# SAM9X75D1GN2 register map
Vendor: Microchip Technology; Series: SAM9X7; File version: 0
Registers are 32-bit, read-write, reset 0x0 unless marked. A register's access mark holds for its fields unless they carry their own. Offsets are from the block's base; [hi:lo] are bit positions.

## SCKC — Slow Clock Controller
Base 0xFFFFFE50
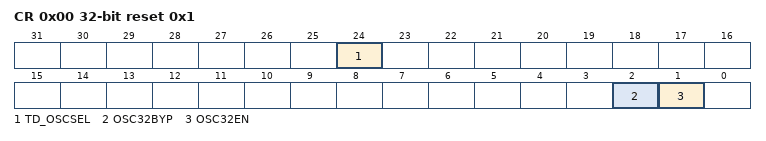
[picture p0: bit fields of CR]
0x00 CR reset 0x1 — Slow Clock Controller Configuration Register
  [24] TD_OSCSEL — Timing Domain Slow Clock Selector
    0=RC (Slow clock of the timing domain is driven by the embedded 32 kHz (typical) RC oscillator.); 1=XTAL (Slow clock of the timing domain is driven by the 32.768 kHz crystal oscillator.)
  [2] OSC32BYP — 32.768 kHz Crystal Oscillator Bypass
    0=32.768 kHz crystal oscillator is not bypassed; 1=32.768 kHz crystal oscillator is bypassed and accepts an external slow clock on XIN32
  [1] OSC32EN — 32.768 kHz Crystal Oscillator
    0=32.768 kHz crystal oscillator is disabled; 1=32.768 kHz crystal oscillator is enabled

## SHDWC — Shutdown Controller
Base 0xFFFFFE10
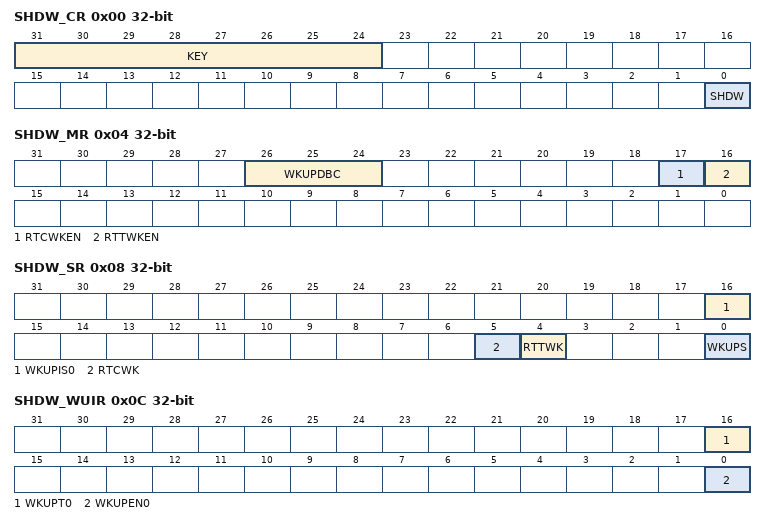
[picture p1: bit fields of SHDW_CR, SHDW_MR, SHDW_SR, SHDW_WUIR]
0x00 SHDW_CR wo — Control Register
  [31:24] KEY — Password
    165=PASSWD (Writing any other value in this field aborts the write operation.)
  [0] SHDW — Shutdown Command
    0=No effect; 1=If KEY value is correct, asserts the SHDN pin
0x04 SHDW_MR — Mode Register
  [26:24] WKUPDBC — Wake-up Inputs Debouncer Period
    0=IMMEDIATE (Immediate, no debouncing, detected active at least on one MD_SLCK edge.); 1=3_SLCK (WKUP shall be in its active state for at least 3 MD_SLCK periods); 2=32_SLCK (WKUP shall be in its active state for at least 32 MD_SLCK periods); 3=512_SLCK (WKUP shall be in its active state for at least 512 MD_SLCK periods); 4=4096_SLCK (WKUP shall be in its active state for at least 4,096 MD_SLCK periods); 5=32768_SLCK (WKUP shall be in its active state for at least 32,768 MD_SLCK periods)
  [17] RTCWKEN — Real-time Clock Wake-up Enable
    0=The RTC Alarm signal has no effect on the SHDWC; 1=The RTC Alarm signal forces the de-assertion of the SHDN pin
  [16] RTTWKEN — Real-time Timer Wake-up Enable
    0=The RTT Alarm signal has no effect on the SHDWC; 1=The RTT Alarm signal forces the de-assertion of the SHDN pin
0x08 SHDW_SR ro — Status Register
  [16] WKUPIS0 — Wake-up 0 Input Status
    0=DISABLE (The wake-up 0 input is disabled, or was inactive at the time the debouncer triggered a wake-up event.); 1=ENABLE (The wake-up 0 input was active at the time the debouncer triggered a wake-up event.)
  [5] RTCWK — Real-time Clock Wake-up
    0=No wake-up alarm from the RTC occurred since the last read of SHDW_SR; 1=At least one wake-up alarm from the RTC occurred since the last read of SHDW_SR
  [4] RTTWK — Real-time Timer Wake-up
    0=No wake-up alarm from the RTT occurred since the last read of SHDW_SR; 1=At least one wake-up alarm from the RTT occurred since the last read of SHDW_SR
  [0] WKUPS — WKUP Wake-up Status
    0=NO (No wake-up due to the assertion of the WKUP pin has occurred since the last read of SHDW_SR.); 1=PRESENT (At least one wake-up due to the assertion of the WKUP pin has occurred since the last read of SHDW_SR.)
0x0C SHDW_WUIR — Wake-up Inputs Register
  [16] WKUPT0 — Wake-up 0 Input Type
    0=LOW (A falling edge followed by a low level on the wake-up 0 input, for a period defined by WKUPDBC, forces wake-up of the core power supply.); 1=HIGH (A rising edge followed by a high level on the wake-up 0 input, for a period defined by WKUPDBC, forces wake-up of the core power supply.)
  [0] WKUPEN0 — Wake-up 0 Input Enable
    0=DISABLE (The wake-up 0 input has no wake-up effect.); 1=ENABLE (The wake-up 0 input forces wake-up of the core power supply.)

## SYSCWP — External Interrupt Controller
Base 0xFFFFFEDC
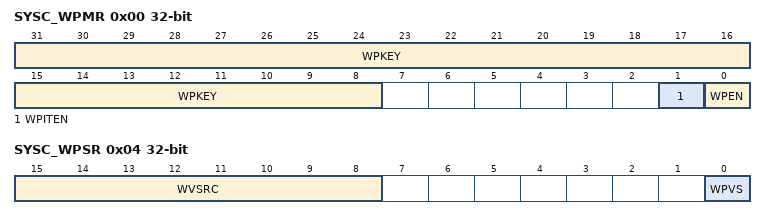
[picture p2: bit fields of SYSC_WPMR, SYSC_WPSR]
0x00 SYSC_WPMR — Write Protection Mode Register
  [31:8] WPKEY — Write Protection Key
    0x535943=PASSWD (Writing any other value in this field aborts the write operation of the WPEN and WPITEN bits. Always reads as 0.)
  [1] WPITEN — Write Protection RTC Interrupt Enable
    0=Disables the write protection of the RTC_IER/RTC_IDR configuration registers if WPKEY corresponds to 0x535943 ('SYC' in ASCII); 1=Enables the write protection of the RTC_IER/RTC_IDR configuration registers if WPKEY corresponds to 0x535943 ('SYC' in ASCII)
  [0] WPEN — Write Protection Enable
    0=Disables the write protection of the configuration registers if WPKEY corresponds to 0x535943 ('SYC' in ASCII); 1=Enables the write protection of the configuration registers if WPKEY corresponds to 0x535943 ('SYC' in ASCII)
0x04 SYSC_WPSR ro — Write Protection Status Register
  [15:8] WVSRC — Write Violation Source
  [0] WPVS — Write Protection Register Violation Status
    0=No write protection violation has occurred since the last read of SYSC_WPSR; 1=A write protection violation has occurred since the last read of SYSC_WPSR. The associated violation is reported into field WVSRC.

## WDT — Watchdog Timer
Base 0xFFFFFF80
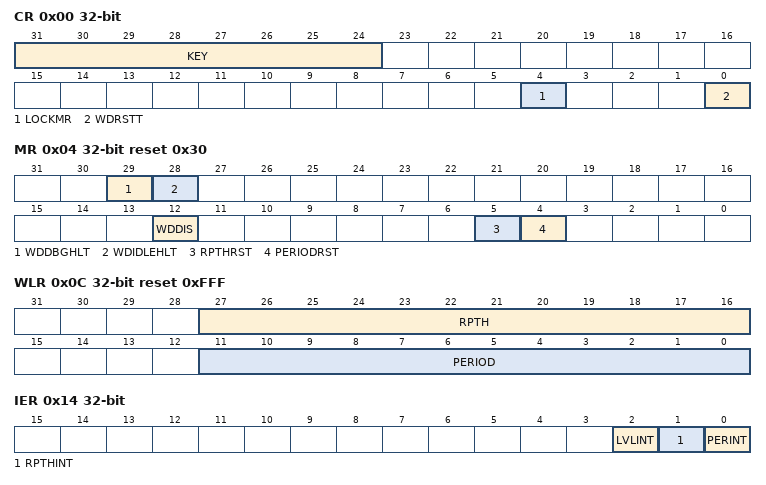
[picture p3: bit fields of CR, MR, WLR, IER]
0x00 CR wo — Control Register
  [31:24] KEY — Password
    165=PASSWD (Writing any other value in this field aborts the write operation.)
  [4] LOCKMR — Lock Mode Register Write Access
    0=No effect; 1=Locks the configuration registers if KEY is written to 0xA5. Write accesses to WDT_MR, WDT_WLR and WDT_ILR have no effect.
  [0] WDRSTT — Watchdog Restart
    0=No effect; 1=Restarts the WDT if KEY is written to 0xA5
0x04 MR reset 0x30 — Mode Register
  [29] WDDBGHLT — Watchdog Debug Halt
    0=The WDT runs when the processor is in Debug state; 1=The WDT stops when the processor is in Debug state
  [28] WDIDLEHLT — Watchdog Idle Halt
    0=The WDT runs when the system is in Idle state; 1=The WDT stops when the system is in Idle state
  [12] WDDIS — Watchdog Disable
    0=Enables the WDT; 1=Disables the WDT
  [5] RPTHRST — Minimum Restart Period
    0=No reset is generated if the WDT is restarted before the RPTH threshold; 1=A reset is generated if the WDT is restarted before the RPTH threshold
  [4] PERIODRST — Period Reset
    0=No reset is generated if the WDT down counter reaches 0; 1=A reset is generated once the WDT down counter reaches 0
0x08 VR ro — Value Register
  [11:0] COUNTER — Watchdog Down Counter Value
0x0C WLR reset 0xFFF — Window Level Register
  [27:16] RPTH — Repeat Threshold
  [11:0] PERIOD — Watchdog Period
0x10 ILR reset 0xFFF — Interrupt Level Register
  [11:0] LVLTH — Level Threshold
0x14 IER wo — Interrupt Enable Register
  [2] LVLINT — Interrupt Level Threshold Interrupt Enable
  [1] RPTHINT — Repeat Threshold Interrupt Enable
  [0] PERINT — Period Interrupt Enable
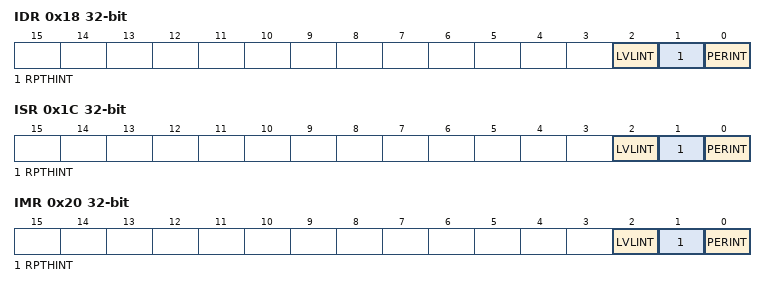
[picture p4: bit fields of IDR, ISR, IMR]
0x18 IDR wo — Interrupt Disable Register
  [2] LVLINT — Interrupt Level Threshold Interrupt Disable
  [1] RPTHINT — Repeat Threshold Interrupt Disable
  [0] PERINT — Period Interrupt Disable
0x1C ISR ro — Interrupt Status Register
  [2] LVLINT — Interrupt Level Threshold Interrupt Status (cleared on read)
    0=No level threshold failure has occurred in the WDT since the last read of WDT_ISR; 1=At least one level threshold failure has occurred in the WDT since the last read of WDT_ISR
  [1] RPTHINT — Repeat Threshold Interrupt Status (cleared on read)
    0=No repeat threshold failure has occurred in the WDT since the last read of WDT_ISR; 1=At least one repeat threshold failure has occurred in the WDT since the last read of WDT_ISR
  [0] PERINT — Period Interrupt Status (cleared on read)
    0=No period failure has occurred in the WDT since the last read of WDT_ISR; 1=At least one period failure has occurred in the WDT since the last read of WDT_ISR
0x20 IMR ro — Interrupt Mask Register
  [2] LVLINT — Interrupt Level Threshold Interrupt Mask
  [1] RPTHINT — Repeat Threshold Interrupt Mask
  [0] PERINT — Period Interrupt Mask
